# RZT2M register map
Vendor: Renesas Electronics Corporation; Series: RZT; File version: 1.20.01
CPU: other r0p0, little endian, MPU, no FPU, VTOR, 4 interrupt priority bits, 624 interrupts
Registers are 32-bit, read-write, reset 0x0 unless marked. A register's access mark holds for its fields unless they carry their own. Offsets are from the block's base; [hi:lo] are bit positions; {n}, {i} and the like mark numbered series; 'fields as' and 'values as' point back to an identical list.

## SEM — Semaphore
Base 0x80281000
0x00 SYTSEMFEN — Semaphore Enable Register
  [0] SEMFEN — Semaphore Enable
    0=Read clear function disabled; 1=Read clear function enabled
{0x10+4i} SYTSEMF{i} (i=0..7) — Semaphore Register {i}
  [0] SEMF — Semaphore
    0=Resource is used; 1=Resource is not used

## ELO — Evnet Link Option Setting
Base 0x80281200
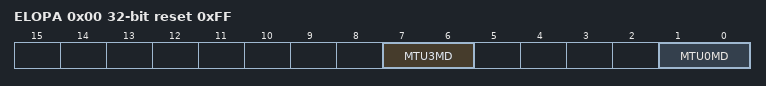
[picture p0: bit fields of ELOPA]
0x00 ELOPA reset 0xFF — Event Link Option Setting Register A
  [7:6] MTU3MD — MTU3 Operation Select
    0=Counting is started; 1=Counting is restarted; 2=Input capture (The MTU3.TCNT value is captured into MTU3.TGRA.); 3=Event is disabled
  [1:0] MTU0MD — MTU0 Operation Select
    0=Counting is started; 1=Counting is restarted; 2=Input capture (The MTU0.TCNT value is captured into MTU0.TGRA.); 3=Event is disabled
0x04 ELOPB reset 0xFF — Event Link Option Setting Register B
  [1:0] MTU4MD — MTU4 Operation Select
    0=Counting is started; 1=Counting is restarted; 2=Input capture (The MTU4.TCNT value is captured into MTU4.TGRA.); 3=Event is disabled

## RWP_NS — Register Write Protection for Non-safety Area
Base 0x80281A10
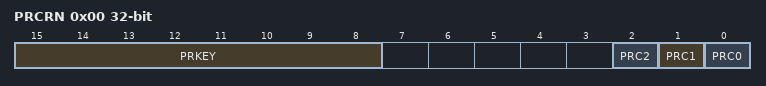
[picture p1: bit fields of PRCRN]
0x00 PRCRN — Non_Safety Area Protect Register
  [15:8] PRKEY wo — PRC Key Code
  [2] PRC2 — Protect 2
    0=Write disabled; 1=Write enabled
  [1] PRC1 — Protect 1
    0=Write disabled; 1=Write enabled
  [0] PRC0 — Protect 0
    0=Write disabled; 1=Write enabled

## OTP — One-Time Programmable Memory
Base 0x81028000
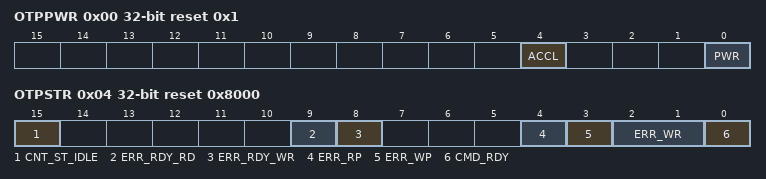
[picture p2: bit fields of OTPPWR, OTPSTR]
0x00 OTPPWR reset 0x1 — OTP Power Control Register
  [4] ACCL — Selects OTP access I/F
    0=Not selected; 1=Selected
  [0] PWR — OTP power on/off setting
    0=Power off; 1=Power on
0x04 OTPSTR reset 0x8000 — OTP Access Status Register
  [15] CNT_ST_IDLE ro — Indicates status of OTP controller
    0=Busy; 1=Idle
  [9] ERR_RDY_RD — OTP read command ready error
  [8] ERR_RDY_WR — OTP write command ready error
  [4] ERR_RP ro — Read protection error
  [3] ERR_WP ro — Write protection error
  [2:1] ERR_WR ro — OTP write status
    0=PASS; 1=Fail due to overwrites; 2=Fail due to compare mismatch; 3=Fail due to overwrites and compare mismatch
  [0] CMD_RDY ro — Indicates whether OTP controller is ready to receive command or not.
    0=Not ready; 1=Ready
0x08 OTPSTAWR — OTP Write Command Register
  [0] STAWR — OTP write start
0x0C OTPADRWR — OTP Write Address Register
  [8:0] ADRWR — OTP write address
0x10 OTPDATAWR — OTP Write Data Register
  [15:0] DATAWR — OTP write data
0x14 OTPADRRD — OTP Read Address Register
  [8:0] ADRRD — OTP read address
0x18 OTPDATARD ro — OTP Read Data Register
  [15:0] DATARD — OTP read data

## PTADR — Port Address Selection
Base 0x81030C00
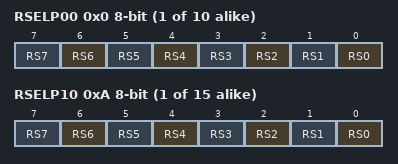
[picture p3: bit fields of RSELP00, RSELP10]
{0x0+i} RSELP0{i} (i=0..9) 8-bit — Port {i} Region Select Register
  [all] fields
    0=Safety region (Address is 0x8103_0xxx); 1=Non safety region (Address is 0x800A_0xxx)
  [n] RS{n} (n=0..7) — Pm_n pin I/O port registers Region Select (n = bit position)
{0x0+i} RSELP{i} (i=10..24) 8-bit — Port {i} Region Select Register
  fields as RSELP00

## SYSC_S — Register Write Protection for Safety Area
Base 0x81280000
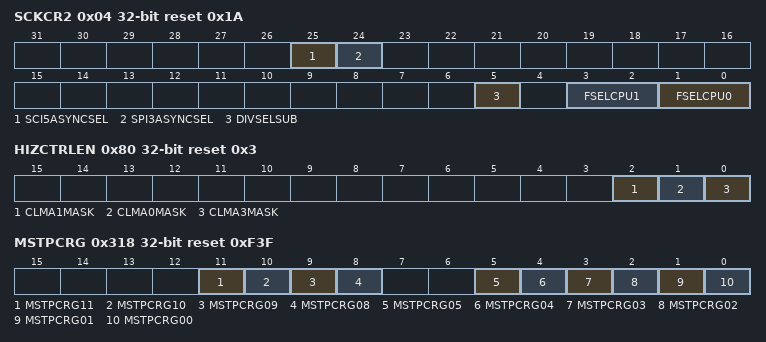
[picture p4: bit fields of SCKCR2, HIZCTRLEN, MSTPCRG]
0x04 SCKCR2 reset 0x1A — System Clock Control Register 2
  [25] SCI5ASYNCSEL — Select clock frequency when asynchronous serial clock is selected in SCI5
    0=75.0 MHz; 1=96.0 MHz
  [24] SPI3ASYNCSEL — Select clock frequency when asynchronous serial clock is selected in SPI3
    0=75.0 MHz; 1=96.0 MHz
  [5] DIVSELSUB — Select the base clock frequency for peripheral module.
  [3:2] FSELCPU1 — Set the frequency of the clock provided to Coretex-R52 CPU1 in combination with bit 5 (DIVSELSUB).
  [1:0] FSELCPU0 — Set the frequency of the clock provided to Coretex-R52 CPU0 in combination with bit 5 (DIVSELSUB). The combination is shown below.
0x20 PLL0MON ro reset 0x1 — PLL0 Monitor Register
  [0] PLL0MON — PLL0 Lock State Monitor
    0=PLL0 is not locked; 1=PLL0 is locked
0x40 PLL1MON ro (reset mask 0xFFFFFFFE) — PLL1 Monitor Register
  [0] PLL1MON — PLL1 Lock State Monitor
    0=PLL1 is not locked; 1=PLL1 is locked
0x50 PLL1EN (reset mask 0xFFFFFFFE) — PLL1 Enable Register
  [0] PLL1EN — PLL1 Enable
    0=PLL1 is in standby state; 1=PLL1 is in normal state
0x70 LOCOCR — Low-Speed On-Chip Oscillator Control Register
  [0] LCSTP — LOCO Stop
    0=Stop; 1=Run
0x80 HIZCTRLEN reset 0x3 — High-Impedance Control Enable Register
  [2] CLMA1MASK — CLMA1 error mask to POE3 and POEG
    0=CLMA1 error is not transferred to POE3 and POEG; 1=CLMA1 error is transferred to POE3 and POEG
  [1] CLMA0MASK — CLMA0 error mask to POE3 and POEG
    0=CLMA0 error is not transferred to POE3 and POEG; 1=CLMA0 error is transferred to POE3 and POEG
  [0] CLMA3MASK — CLMA3 error mask to POE3 and POEG
    0=CLMA3 error is not transferred to POE3 and POEG; 1=CLMA3 error is transferred to POE3 and POEG
0x210 SWRSYS wo — System Software Reset Register
  [31:0] SWR — System Software Reset
0x220 SWRCPU0 — CPU0 Software Reset Register
  [31:0] SWR — CPU0 Software Reset
0x230 SWRCPU1 reset 0x1 — CPU1 Software Reset Register
  [31:0] SWR — CPU1 Software Reset
0x314 MSTPCRF — Module Stop Control Register F
  [0] MSTPCRF00 — Trace Clock for Debugging Interface Module Stop
    0=Release from the module-stop state; 1=Transition to the module-stop state is made
0x318 MSTPCRG reset 0xF3F — Module Stop Control Register G
  [all] fields
    values as MSTPCRF.MSTPCRF00
  [11] MSTPCRG11 — CLMA2 Module Stop
  [10] MSTPCRG10 — CLMA1 Module Stop
  [9] MSTPCRG09 — CLMA0 Module Stop
  [8] MSTPCRG08 — CLMA3 Module Stop
  [5] MSTPCRG05 — RTC Module Stop
  [4] MSTPCRG04 — CRC Unit 1 Module Stop
  [3] MSTPCRG03 — GPT Unit 2 Module Stop
  [2] MSTPCRG02 — SPI Unit 3 Module Stop
  [1] MSTPCRG01 — IIC Unit 2 Module Stop
  [0] MSTPCRG00 — SCI Unit 5 Module Stop
0x31C MSTPCRH (reset mask 0xFFFFFFFD) — Module Stop Control Register H
  [1] MSTPCRH01 — CPU1 Module Stop
    values as MSTPCRF.MSTPCRF00
